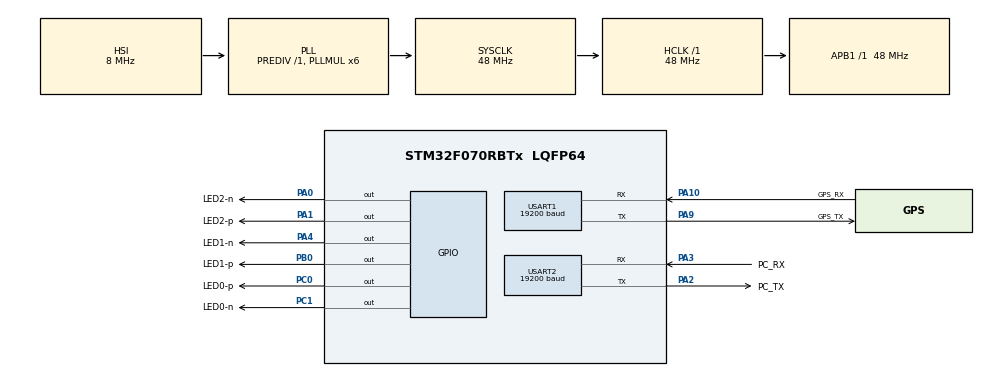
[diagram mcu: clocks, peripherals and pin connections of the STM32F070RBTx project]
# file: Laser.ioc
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FREERTOS.Tasks01=defaultTask,0,128,StartDefaultTask
Mcu.Family=STM32F0
Mcu.Name=STM32F070RBTx
Mcu.Package=LQFP64
PA0.GPIO_Label=LED2-n
PA0.Signal=GPIO_Output
PA1.GPIO_Label=LED2-p
PA1.Signal=GPIO_Output
PA10.GPIO_Label=GPS_RX
PA10.Mode=Asynchronous
PA10.Signal=USART1_RX
PA2.GPIO_Label=PC_TX
PA2.Mode=Asynchronous
PA2.Signal=USART2_TX
PA3.GPIO_Label=PC_RX
PA3.Mode=Asynchronous
PA3.Signal=USART2_RX
PA4.GPIO_Label=LED1-n
PA4.Signal=GPIO_Output
PA9.GPIO_Label=GPS_TX
PA9.Mode=Asynchronous
PA9.Signal=USART1_TX
PB0.GPIO_Label=LED1-p
PB0.Signal=GPIO_Output
PC0.GPIO_Label=LED0-p
PC0.Signal=GPIO_Output
PC1.GPIO_Label=LED0-n
PC1.Signal=GPIO_Output
ProjectManager.TargetToolchain=SW4STM32
RCC.AHBFreq_Value=48000000
RCC.APB1Freq_Value=48000000
RCC.APB1TimFreq_Value=48000000
RCC.HCLKFreq_Value=48000000
RCC.PLLMUL=RCC_PLL_MUL6
RCC.SYSCLKFreq_VALUE=48000000
RCC.SYSCLKSource=RCC_SYSCLKSOURCE_PLLCLK
USART1.BaudRate=19200
USART1.WordLength=UART_WORDLENGTH_8B
USART2.BaudRate=19200
USART2.WordLength=UART_WORDLENGTH_8B
VP_FREERTOS_VS_ENABLE.Mode=Enabled
board=NUCLEO-F070RB

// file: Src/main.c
/**
  ******************************************************************************
  * File Name          : main.c
  * Description        : Main program body
  ******************************************************************************
  *
  * COPYRIGHT(c) 2016 STMicroelectronics
  *
  * Redistribution and use in source and binary forms, with or without modification,
  * are permitted provided that the following conditions are met:
  *   1. Redistributions of source code must retain the above copyright notice,
  *      this list of conditions and the following disclaimer.
  *   2. Redistributions in binary form must reproduce the above copyright notice,
  *      this list of conditions and the following disclaimer in the documentation
  *      and/or other materials provided with the distribution.
  *   3. Neither the name of STMicroelectronics nor the names of its contributors
  *      may be used to endorse or promote products derived from this software
  *      without specific prior written permission.
  *
  * THIS SOFTWARE IS PROVIDED BY THE COPYRIGHT HOLDERS AND CONTRIBUTORS "AS IS"
  * AND ANY EXPRESS OR IMPLIED WARRANTIES, INCLUDING, BUT NOT LIMITED TO, THE
  * IMPLIED WARRANTIES OF MERCHANTABILITY AND FITNESS FOR A PARTICULAR PURPOSE ARE
  * DISCLAIMED. IN NO EVENT SHALL THE COPYRIGHT HOLDER OR CONTRIBUTORS BE LIABLE
  * FOR ANY DIRECT, INDIRECT, INCIDENTAL, SPECIAL, EXEMPLARY, OR CONSEQUENTIAL
  * DAMAGES (INCLUDING, BUT NOT LIMITED TO, PROCUREMENT OF SUBSTITUTE GOODS OR
  * SERVICES; LOSS OF USE, DATA, OR PROFITS; OR BUSINESS INTERRUPTION) HOWEVER
  * CAUSED AND ON ANY THEORY OF LIABILITY, WHETHER IN CONTRACT, STRICT LIABILITY,
  * OR TORT (INCLUDING NEGLIGENCE OR OTHERWISE) ARISING IN ANY WAY OUT OF THE USE
  * OF THIS SOFTWARE, EVEN IF ADVISED OF THE POSSIBILITY OF SUCH DAMAGE.
  *
  ******************************************************************************
  */
#include "stm32f0xx_hal.h"
#include "cmsis_os.h"

UART_HandleTypeDef huart1;
UART_HandleTypeDef huart2;

osThreadId defaultTaskHandle;

/* USER CODE BEGIN PV */
/* Private variables ---------------------------------------------------------*/

/* USER CODE END PV */

void SystemClock_Config(void);
static void MX_GPIO_Init(void);
static void MX_USART1_UART_Init(void);
static void MX_USART2_UART_Init(void);
void StartDefaultTask(void const * argument);

/* USER CODE BEGIN PFP */
/* Private function prototypes -----------------------------------------------*/

/* USER CODE END PFP */

static void strToUART(char * msg)
{
	HAL_UART_Transmit(&huart2, (uint8_t*)msg, strlen(msg), 0xFFFF);
}

int main(void)
{

  /* MCU Configuration----------------------------------------------------------*/

  /* Reset of all peripherals, Initializes the Flash interface and the Systick. */
  HAL_Init();

  /* Configure the system clock */
  SystemClock_Config();

  /* Initialize all configured peripherals */
  MX_GPIO_Init();
  MX_USART1_UART_Init();
  MX_USART2_UART_Init();

  /* Create the thread(s) */
  /* definition and creation of defaultTask */
  osThreadDef(defaultTask, StartDefaultTask, osPriorityNormal, 0, 128);
  defaultTaskHandle = osThreadCreate(osThread(defaultTask), NULL);

  /* Start scheduler */
  osKernelStart();

  /* We should never get here as control is now taken by the scheduler */

  /* Infinite loop */
  while (1)
  {

  }

}

/** System Clock Configuration
*/
void SystemClock_Config(void)
{

  RCC_OscInitTypeDef RCC_OscInitStruct;
  RCC_ClkInitTypeDef RCC_ClkInitStruct;
  RCC_PeriphCLKInitTypeDef PeriphClkInit;

  RCC_OscInitStruct.OscillatorType = RCC_OSCILLATORTYPE_HSI;
  RCC_OscInitStruct.HSIState = RCC_HSI_ON;
  RCC_OscInitStruct.HSICalibrationValue = 16;
  RCC_OscInitStruct.PLL.PLLState = RCC_PLL_ON;
  RCC_OscInitStruct.PLL.PLLSource = RCC_PLLSOURCE_HSI;
  RCC_OscInitStruct.PLL.PLLMUL = RCC_PLL_MUL6;
  RCC_OscInitStruct.PLL.PREDIV = RCC_PREDIV_DIV1;
  HAL_RCC_OscConfig(&RCC_OscInitStruct);

  RCC_ClkInitStruct.ClockType = RCC_CLOCKTYPE_SYSCLK;
  RCC_ClkInitStruct.SYSCLKSource = RCC_SYSCLKSOURCE_PLLCLK;
  RCC_ClkInitStruct.AHBCLKDivider = RCC_SYSCLK_DIV1;
  RCC_ClkInitStruct.APB1CLKDivider = RCC_HCLK_DIV1;
  HAL_RCC_ClockConfig(&RCC_ClkInitStruct, FLASH_LATENCY_1);

  PeriphClkInit.PeriphClockSelection = RCC_PERIPHCLK_USART1;
  PeriphClkInit.Usart1ClockSelection = RCC_USART1CLKSOURCE_PCLK1;
  HAL_RCCEx_PeriphCLKConfig(&PeriphClkInit);

  HAL_SYSTICK_Config(HAL_RCC_GetHCLKFreq()/1000);

  HAL_SYSTICK_CLKSourceConfig(SYSTICK_CLKSOURCE_HCLK);

  /* SysTick_IRQn interrupt configuration */
  HAL_NVIC_SetPriority(SysTick_IRQn, 3, 0);
}

/* USART1 init function */
void MX_USART1_UART_Init(void)
{

  huart1.Instance = USART1;
  huart1.Init.BaudRate = 19200;
  huart1.Init.WordLength = UART_WORDLENGTH_8B;
  huart1.Init.StopBits = UART_STOPBITS_1;
  huart1.Init.Parity = UART_PARITY_NONE;
  huart1.Init.Mode = UART_MODE_TX_RX;
  huart1.Init.HwFlowCtl = UART_HWCONTROL_NONE;
  huart1.Init.OverSampling = UART_OVERSAMPLING_16;
  huart1.Init.OneBitSampling = UART_ONEBIT_SAMPLING_DISABLED ;
  huart1.AdvancedInit.AdvFeatureInit = UART_ADVFEATURE_NO_INIT;
  HAL_UART_Init(&huart1);

}

/* USART2 init function */
void MX_USART2_UART_Init(void)
{

  huart2.Instance = USART2;
  huart2.Init.BaudRate = 19200;
  huart2.Init.WordLength = UART_WORDLENGTH_8B;
  huart2.Init.StopBits = UART_STOPBITS_1;
  huart2.Init.Parity = UART_PARITY_NONE;
  huart2.Init.Mode = UART_MODE_TX_RX;
  huart2.Init.HwFlowCtl = UART_HWCONTROL_NONE;
  huart2.Init.OverSampling = UART_OVERSAMPLING_16;
  huart2.Init.OneBitSampling = UART_ONEBIT_SAMPLING_DISABLED ;
  huart2.AdvancedInit.AdvFeatureInit = UART_ADVFEATURE_NO_INIT;
  HAL_UART_Init(&huart2);

}

/** Configure pins as
        * Analog
        * Input
        * Output
        * EVENT_OUT
        * EXTI
*/
void MX_GPIO_Init(void)
{

  GPIO_InitTypeDef GPIO_InitStruct;

  /* GPIO Ports Clock Enable */
  __GPIOC_CLK_ENABLE();
  __GPIOA_CLK_ENABLE();
  __GPIOB_CLK_ENABLE();

  /*Configure GPIO pins : LED0_p_Pin LED0_n_Pin */
  GPIO_InitStruct.Pin = LED0_p_Pin|LED0_n_Pin;
  GPIO_InitStruct.Mode = GPIO_MODE_OUTPUT_PP;
  GPIO_InitStruct.Pull = GPIO_NOPULL;
  GPIO_InitStruct.Speed = GPIO_SPEED_LOW;
  HAL_GPIO_Init(GPIOC, &GPIO_InitStruct);

  /*Configure GPIO pins : LED2_n_Pin LED2_p_Pin LED1_n_Pin */
  GPIO_InitStruct.Pin = LED2_n_Pin|LED2_p_Pin|LED1_n_Pin;
  GPIO_InitStruct.Mode = GPIO_MODE_OUTPUT_PP;
  GPIO_InitStruct.Pull = GPIO_NOPULL;
  GPIO_InitStruct.Speed = GPIO_SPEED_LOW;
  HAL_GPIO_Init(GPIOA, &GPIO_InitStruct);

  /*Configure GPIO pin : LED1_p_Pin */
  GPIO_InitStruct.Pin = LED1_p_Pin;
  GPIO_InitStruct.Mode = GPIO_MODE_OUTPUT_PP;
  GPIO_InitStruct.Pull = GPIO_NOPULL;
  GPIO_InitStruct.Speed = GPIO_SPEED_LOW;
  HAL_GPIO_Init(LED1_p_GPIO_Port, &GPIO_InitStruct);

}

/* StartDefaultTask function */
void StartDefaultTask(void const * argument)
{

  /* USER CODE BEGIN 5 */
	uint8_t * req = "r";
	uint8_t in[7];
	uint8_t * nl = "\n\r";
	uint8_t inSize;
	HAL_StatusTypeDef status;

	//char * i = "moo\n\r";

	//laserIn = {'0','1','2','3'};
	HAL_GPIO_WritePin(GPIOC, GPIO_PIN_0, GPIO_PIN_RESET);
  /* Infinite loop */
	//HAL_UART_Transmit(&huart1, (uint8_t *)i, 1, 1000);
  for(;;)
  {
	  status = HAL_UART_Transmit(&huart1, (uint8_t *)req, 1, 1000);	// request data from laser
	  if(status == HAL_OK)
	  {
	  	for (inSize = 0; status == HAL_OK; inSize++)
	  	{
	  		status = HAL_UART_Receive(&huart1, &in[inSize], 1, 0x500);
	  	}
	  	if(status != HAL_OK)	inSize--;
	  	HAL_UART_Transmit(&huart2, (uint8_t *)in, inSize-1, 0x1000);
	  	strToUART(nl);
	  	//osDelay(100);
	  }
	  /*
	  char laserIn[20];
	  //*laserIn = NULL;
	  if(HAL_UART_Transmit(&huart1, (uint8_t *)i, 1, 1000) == HAL_OK)
	  {
		  HAL_StatusTypeDef status = HAL_UART_Receive(&huart1, (uint8_t *)laserIn, 3, 0xFFFF);
		  if(status == HAL_OK)
		  {
			  // send back to pc.
			  strToUART(laserIn);
		  }
		  else strToUART("Did not receive.\n\r");
	  }
	  else strToUART("Did not transmit.\n\r");
	  //HAL_UART_Transmit(&huart2, (uint8_t *)i, 2, 1000);
	  //osDelay(10);
	  //HAL_UART_Receive(&huart1, (uint8_t *)laserIn, 8, 1000);
	  //osDelay(100);
	  //HAL_UART_Transmit(&huart2, (uint8_t *)laserIn, strlen(laserIn), 1000);
	  //osDelay(1000);
	  //HAL_UART_Transmit(&huart2, nl, strlen(nl), 1000);
	  //HAL_UART_Transmit(&huart2, laserIn, strlen(laserIn), 1000);
	  HAL_GPIO_TogglePin(GPIOC, GPIO_PIN_1);
	  osDelay(1000);
	  */
  }
  /* USER CODE END 5 */
}

/************************ (C) COPYRIGHT STMicroelectronics *****END OF FILE****/
